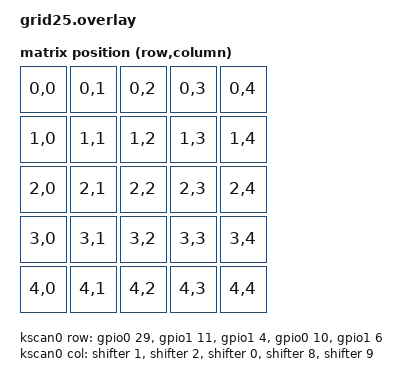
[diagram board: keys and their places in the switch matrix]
// This file was generated from a template. Edit it to match your keyboard.
// See https://zmk.dev/docs/development/hardware-integration/new-shield for more
// instructions.

#include <dt-bindings/zmk/matrix_transform.h>
#include <dt-bindings/led/led.h>
#include "grid25-layouts.dtsi"

/ {
    chosen {
        zmk,physical-layout = &physical_layout0;
        zmk,underglow = &led_strip;
    };


    

    kscan0: kscan {
        // If the hardware does not use a switch matrix, change this to the
        // appropriate driver and update the properties below to match.
        // See https://zmk.dev/docs/config/kscan for supported key scan drivers.
        compatible = "zmk,kscan-gpio-matrix";
        // Set this to "col2row" or "row2col" to match the hardware. If using
        // "row2col", change the col-gpios to (GPIO_ACTIVE_HIGH | GPIO_PULL_DOWN)
        // and the row-gpios to GPIO_ACTIVE_HIGH.
        diode-direction = "col2row";
        wakeup-source;

        // Replace these comments with the GPIO pins in the matrix.
        // See https://zmk.dev/docs/development/hardware-integration/new-shield#shield-overlays
        col-gpios
            = <&shifter 1 GPIO_ACTIVE_HIGH>
            , <&shifter 2 GPIO_ACTIVE_HIGH>
            , <&shifter 0 GPIO_ACTIVE_HIGH>
            , <&shifter 8 GPIO_ACTIVE_HIGH>
            , <&shifter 9 GPIO_ACTIVE_HIGH>
            ;

        row-gpios
            = <&gpio0 29 (GPIO_ACTIVE_HIGH | GPIO_PULL_DOWN)>
            , <&gpio1 11 (GPIO_ACTIVE_HIGH | GPIO_PULL_DOWN)>
            , <&gpio1 4 (GPIO_ACTIVE_HIGH | GPIO_PULL_DOWN)>
            , <&gpio0 10 (GPIO_ACTIVE_HIGH | GPIO_PULL_DOWN)>
            , <&gpio1 6 (GPIO_ACTIVE_HIGH | GPIO_PULL_DOWN)>
            ;
    };

    matrix_transform0: matrix_transform_0 {
        // See https://zmk.dev/docs/development/hardware-integration/new-shield#matrix-transform
        // for how to configure this
        compatible = "zmk,matrix-transform";
        columns = <5>;
        rows = <5>;

        map = <
            RC(0,0) RC(0,1) RC(0,2) RC(0,3) RC(0,4)
            RC(1,0) RC(1,1) RC(1,2) RC(1,3) RC(1,4)
            RC(2,0) RC(2,1) RC(2,2) RC(2,3) RC(2,4)
            RC(3,0) RC(3,1) RC(3,2) RC(3,3) RC(3,4)
            RC(4,0) RC(4,1) RC(4,2) RC(4,3) RC(4,4)
        >;
    };
    
    //外部电源控制引脚
//    ext-power {
//        compatible = "zmk,ext-power-generic";
//        label = "EXT_POWER";
//        control-gpios = <&gpio0 13 GPIO_ACTIVE_HIGH>; /* 这里指明了 P0.13 */
//        init-delay-ms = <50>;
//    };
    
};


// led 支持 https://zmk.dev/docs/development/hardware-integration/lighting/underglow#nrf52-based-boards
&pinctrl {

    // rgb led
    spi3_default: spi3_default {
        group1 {
            psels = <NRF_PSEL(SPIM_MOSI, 0, 11)>; //led数据引脚
        };
    };

    spi3_sleep: spi3_sleep {
        group1 {
            psels = <NRF_PSEL(SPIM_MOSI, 0, 11)>; //led数据引脚
            low-power-enable;
        };
    };



//74hc595 支持
 spi0_default: spi0_default {
        group1 {
            psels = <NRF_PSEL(SPIM_SCK, 0, 22)>,  //连595的11引脚SRCLK
                    <NRF_PSEL(SPIM_MOSI, 0, 17)>; //连595的14引脚SER
        };
    };
    spi0_sleep: spi0_sleep {
        group1 {
            psels = <NRF_PSEL(SPIM_SCK, 0, 22)>,  //连595的11引脚SRCLK
                    <NRF_PSEL(SPIM_MOSI, 0, 17)>; //连595的14引脚SER
            low-power-enable;
        };
    };

};

&spi3 {
    compatible = "nordic,nrf-spim";
    status = "okay";

    pinctrl-0 = <&spi3_default>;
    pinctrl-1 = <&spi3_sleep>;
    pinctrl-names = "default", "sleep";

    led_strip: ws2812@0 {
        compatible = "worldsemi,ws2812-spi";

        /* SPI */
        reg = <0>; /* ignored, but necessary for SPI bindings */
        spi-max-frequency = <4000000>;

        /* WS2812 */
        chain-length = <25>;  // 灯珠数量
        spi-one-frame = <0x70>;
        spi-zero-frame = <0x40>;
        color-mapping = <LED_COLOR_ID_GREEN
                         LED_COLOR_ID_RED
                         LED_COLOR_ID_BLUE>;
    };
};


// 74hc595 支持
&spi0 {
    compatible = "nordic,nrf-spim";
    status = "okay";
    pinctrl-0 = <&spi0_default>;
    pinctrl-1 = <&spi0_sleep>;
    pinctrl-names = "default", "sleep";

    // 74hc595 RCLK引脚
    cs-gpios = <&gpio0 20 GPIO_ACTIVE_LOW>;

    shifter: 595@0 {
        compatible = "zmk,gpio-595";
        status = "okay";
        gpio-controller;
        spi-max-frequency = <300000>;
        reg = <0>; /* 对应上面 cs-gpios 的索引 0 */
        #gpio-cells = <2>;
        ngpios = <16>;  //595级联数量*8
    };
};

/* 禁用 ZMK 默认的外部电源控制节点，防止系统在睡眠时自动切断电源 */
&ext_power {
    status = "disabled";
};

/* 强制接管 P0.13 引脚（nice!nano v2 的 EXT_VCC 控制引脚），并始终输出高电平 */
&gpio0 {
    ext_vcc_keep_on {
        gpio-hog;
        gpios = <13 GPIO_ACTIVE_HIGH>;
        output-high;
    };
};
